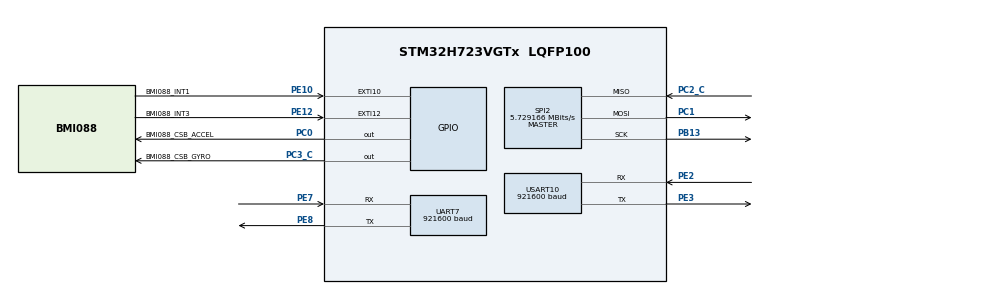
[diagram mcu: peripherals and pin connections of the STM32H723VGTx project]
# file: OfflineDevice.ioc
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CORTEX_M7.CPU_DCache=Enabled
CORTEX_M7.CPU_ICache=Enabled
CORTEX_M7.default_mode_Activation=1
Mcu.Family=STM32H7
Mcu.Name=STM32H723VGTx
Mcu.Package=LQFP100
NVIC.PriorityGroup=NVIC_PRIORITYGROUP_4
NVIC.SPI2_IRQn=true\:3\:0\:true\:false\:true\:true\:true\:true
NVIC.UART7_IRQn=true\:6\:0\:true\:false\:true\:true\:true\:true
NVIC.USART10_IRQn=true\:1\:0\:true\:false\:true\:true\:true\:true
PA13(JTMS/SWDIO).Mode=Serial_Wire
PA13(JTMS/SWDIO).Signal=DEBUG_JTMS-SWDIO
PA14(JTCK/SWCLK).Mode=Serial_Wire
PA14(JTCK/SWCLK).Signal=DEBUG_JTCK-SWCLK
PB13.Mode=Full_Duplex_Master
PB13.Signal=SPI2_SCK
PC0.GPIO_Label=BMI088_CSB_ACCEL
PC0.GPIO_Speed=GPIO_SPEED_FREQ_HIGH
PC0.Signal=GPIO_Output
PC1.Mode=Full_Duplex_Master
PC1.Signal=SPI2_MOSI
PC2_C.Mode=Full_Duplex_Master
PC2_C.Signal=SPI2_MISO
PC3_C.GPIO_Label=BMI088_CSB_GYRO
PC3_C.GPIO_Speed=GPIO_SPEED_FREQ_HIGH
PC3_C.Signal=GPIO_Output
PE10.GPIO_Label=BMI088_INT1
PE10.Signal=GPXTI10
PE12.GPIO_Label=BMI088_INT3
PE12.Signal=GPXTI12
PE2.Mode=Asynchronous
PE2.Signal=USART10_RX
PE3.Mode=Asynchronous
PE3.Signal=USART10_TX
PE7.Mode=Asynchronous
PE7.Signal=UART7_RX
PE8.Mode=Asynchronous
PE8.Signal=UART7_TX
PH0-OSC_IN.Mode=HSE-External-Oscillator
PH0-OSC_IN.Signal=RCC_OSC_IN
PH1-OSC_OUT.Mode=HSE-External-Oscillator
PH1-OSC_OUT.Signal=RCC_OSC_OUT
ProjectManager.HeapSize=0x200
ProjectManager.StackSize=0x400
ProjectManager.TargetToolchain=CMake
RCC.ADCFreq_Value=48375000
RCC.APB1Freq_Value=137500000
RCC.APB2Freq_Value=137500000
RCC.APB3Freq_Value=137500000
RCC.APB4Freq_Value=137500000
RCC.CortexFreq_Value=550000000
RCC.D1PPRE=RCC_APB3_DIV2
RCC.D2PPRE1=RCC_APB1_DIV2
RCC.D2PPRE2=RCC_APB2_DIV2
RCC.D3PPRE=RCC_APB4_DIV2
RCC.DIVM1=3
RCC.DIVN1=68
RCC.DIVP1=1
RCC.DIVQ1=3
RCC.HCLKFreq_Value=275000000
RCC.HPRE=RCC_HCLK_DIV2
RCC.HSE_VALUE=24000000
RCC.PLL2FRACN=0
RCC.PLL3FRACN=0
RCC.PLLFRACN=6144
RCC.PLLSourceVirtual=RCC_PLLSOURCE_HSE
RCC.SPI123ClockSelection=RCC_SPI123CLKSOURCE_CLKP
RCC.SYSCLKFreq_VALUE=550000000
RCC.SYSCLKSource=RCC_SYSCLKSOURCE_PLLCLK
RCC.USBFreq_Value=183333333.33333334
SPI2.BaudRatePrescaler=SPI_BAUDRATEPRESCALER_32
SPI2.CLKPhase=SPI_PHASE_2EDGE
SPI2.CLKPolarity=SPI_POLARITY_HIGH
SPI2.CalculateBaudRate=5.729166 MBits/s
SPI2.DataSize=SPI_DATASIZE_8BIT
SPI2.Direction=SPI_DIRECTION_2LINES
SPI2.FirstBit=SPI_FIRSTBIT_MSB
SPI2.Mode=SPI_MODE_MASTER
SPI2.NSS=SPI_NSS_SOFT
SPI2.VirtualType=VM_MASTER
UART7.BaudRate=921600
USART10.BaudRate=921600
USART10.VirtualMode=VM_ASYNC
VP_MEMORYMAP_VS_MEMORYMAP.Mode=CurAppReg
board=custom

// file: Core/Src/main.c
/* USER CODE BEGIN Header */
/**
  ******************************************************************************
  * @file           : main.c
  * @brief          : Main program body
  ******************************************************************************
  * @attention
  *
  * Copyright (c) 2026 STMicroelectronics.
  * All rights reserved.
  *
  * This software is licensed under terms that can be found in the LICENSE file
  * in the root directory of this software component.
  * If no LICENSE file comes with this software, it is provided AS-IS.
  *
  ******************************************************************************
  */
/* USER CODE END Header */
#include "main.h"
#include "spi.h"
#include "usart.h"
#include "gpio.h"

void SystemClock_Config(void);
static void MPU_Config(void);

int main(void)
{

  /* USER CODE BEGIN 1 */
  /* 姿态识别应用入口（C++ 模块 attitude.app 实现，不返回） */
  extern void attitude_app_main(void);
  /* USER CODE END 1 */

  /* MPU Configuration--------------------------------------------------------*/
  MPU_Config();

  /* Enable the CPU Cache */

  /* Enable I-Cache---------------------------------------------------------*/
  SCB_EnableICache();

  /* Enable D-Cache---------------------------------------------------------*/
  SCB_EnableDCache();

  /* MCU Configuration--------------------------------------------------------*/

  /* Reset of all peripherals, Initializes the Flash interface and the Systick. */
  HAL_Init();

  /* Configure the system clock */
  SystemClock_Config();

  /* Initialize all configured peripherals */
  MX_GPIO_Init();
  MX_USART10_UART_Init();
  MX_UART7_Init();
  MX_SPI2_Init();

  /* Infinite loop */
  while (1)
  {

    /* USER CODE BEGIN 3 */
    attitude_app_main();
  }
  /* USER CODE END 3 */
}

void SystemClock_Config(void)
{
  RCC_OscInitTypeDef RCC_OscInitStruct = {0};
  RCC_ClkInitTypeDef RCC_ClkInitStruct = {0};

  /** Supply configuration update enable
  */
  HAL_PWREx_ConfigSupply(PWR_LDO_SUPPLY);

  /** Configure the main internal regulator output voltage
  */
  __HAL_PWR_VOLTAGESCALING_CONFIG(PWR_REGULATOR_VOLTAGE_SCALE0);

  while(!__HAL_PWR_GET_FLAG(PWR_FLAG_VOSRDY)) {}

  /** Initializes the RCC Oscillators according to the specified parameters
  * in the RCC_OscInitTypeDef structure.
  */
  RCC_OscInitStruct.OscillatorType = RCC_OSCILLATORTYPE_HSE;
  RCC_OscInitStruct.HSEState = RCC_HSE_ON;
  RCC_OscInitStruct.PLL.PLLState = RCC_PLL_ON;
  RCC_OscInitStruct.PLL.PLLSource = RCC_PLLSOURCE_HSE;
  RCC_OscInitStruct.PLL.PLLM = 3;
  RCC_OscInitStruct.PLL.PLLN = 68;
  RCC_OscInitStruct.PLL.PLLP = 1;
  RCC_OscInitStruct.PLL.PLLQ = 3;
  RCC_OscInitStruct.PLL.PLLR = 2;
  RCC_OscInitStruct.PLL.PLLRGE = RCC_PLL1VCIRANGE_3;
  RCC_OscInitStruct.PLL.PLLVCOSEL = RCC_PLL1VCOWIDE;
  RCC_OscInitStruct.PLL.PLLFRACN = 6144;
  if (HAL_RCC_OscConfig(&RCC_OscInitStruct) != HAL_OK)
  {
    Error_Handler();
  }

  /** Initializes the CPU, AHB and APB buses clocks
  */
  RCC_ClkInitStruct.ClockType = RCC_CLOCKTYPE_HCLK|RCC_CLOCKTYPE_SYSCLK
                              |RCC_CLOCKTYPE_PCLK1|RCC_CLOCKTYPE_PCLK2
                              |RCC_CLOCKTYPE_D3PCLK1|RCC_CLOCKTYPE_D1PCLK1;
  RCC_ClkInitStruct.SYSCLKSource = RCC_SYSCLKSOURCE_PLLCLK;
  RCC_ClkInitStruct.SYSCLKDivider = RCC_SYSCLK_DIV1;
  RCC_ClkInitStruct.AHBCLKDivider = RCC_HCLK_DIV2;
  RCC_ClkInitStruct.APB3CLKDivider = RCC_APB3_DIV2;
  RCC_ClkInitStruct.APB1CLKDivider = RCC_APB1_DIV2;
  RCC_ClkInitStruct.APB2CLKDivider = RCC_APB2_DIV2;
  RCC_ClkInitStruct.APB4CLKDivider = RCC_APB4_DIV2;

  if (HAL_RCC_ClockConfig(&RCC_ClkInitStruct, FLASH_LATENCY_3) != HAL_OK)
  {
    Error_Handler();
  }
}

 /* MPU Configuration */

void MPU_Config(void)
{
  MPU_Region_InitTypeDef MPU_InitStruct = {0};

  /* Disables the MPU */
  HAL_MPU_Disable();

  /** Initializes and configures the Region and the memory to be protected
  */
  MPU_InitStruct.Enable = MPU_REGION_ENABLE;
  MPU_InitStruct.Number = MPU_REGION_NUMBER0;
  MPU_InitStruct.BaseAddress = 0x0;
  MPU_InitStruct.Size = MPU_REGION_SIZE_4GB;
  MPU_InitStruct.SubRegionDisable = 0x87;
  MPU_InitStruct.TypeExtField = MPU_TEX_LEVEL0;
  MPU_InitStruct.AccessPermission = MPU_REGION_NO_ACCESS;
  MPU_InitStruct.DisableExec = MPU_INSTRUCTION_ACCESS_DISABLE;
  MPU_InitStruct.IsShareable = MPU_ACCESS_SHAREABLE;
  MPU_InitStruct.IsCacheable = MPU_ACCESS_NOT_CACHEABLE;
  MPU_InitStruct.IsBufferable = MPU_ACCESS_NOT_BUFFERABLE;

  HAL_MPU_ConfigRegion(&MPU_InitStruct);
  /* Enables the MPU */
  HAL_MPU_Enable(MPU_PRIVILEGED_DEFAULT);

}

void Error_Handler(void)
{
  __disable_irq();
  while (1)
  {
  }
}
